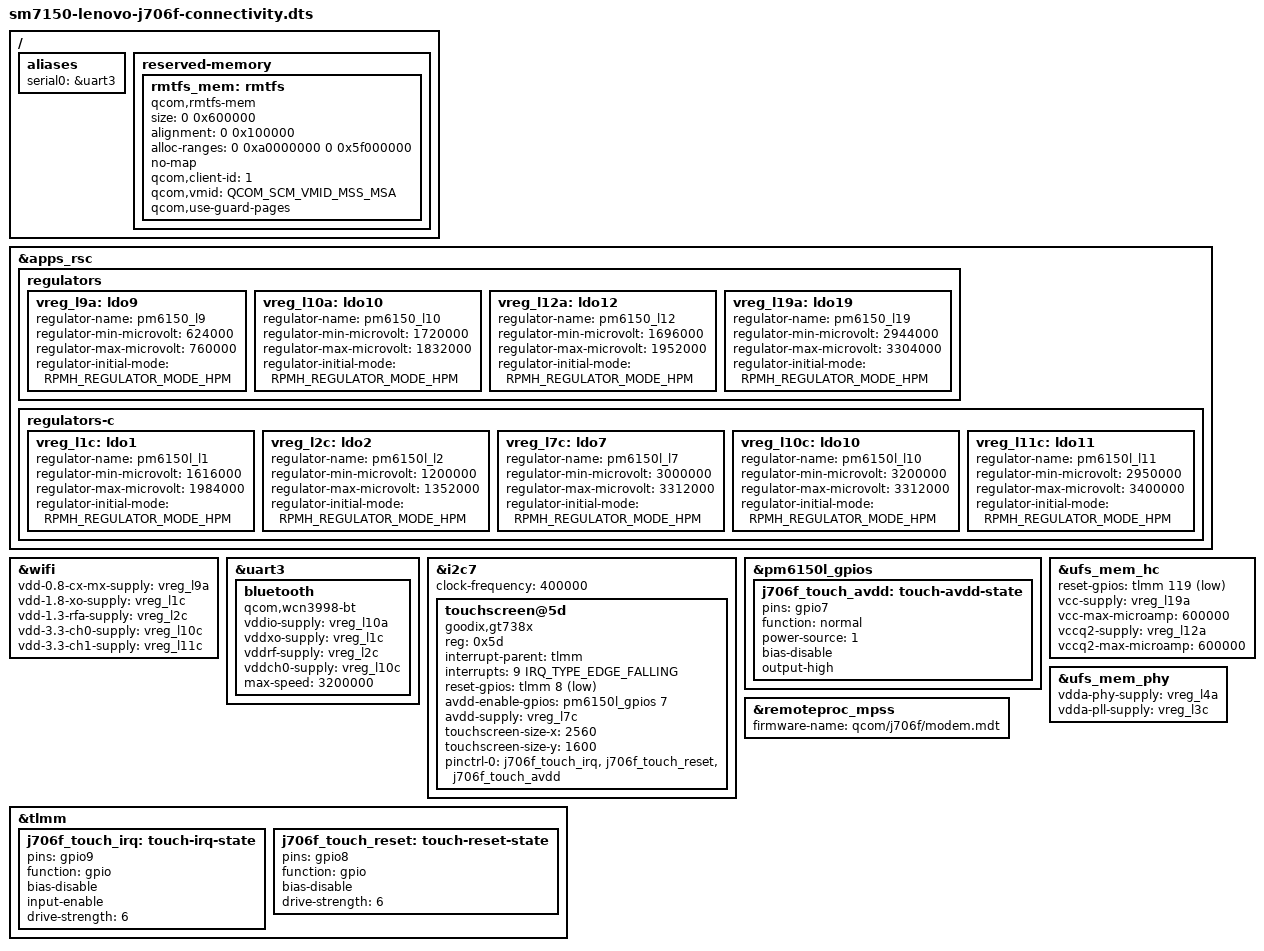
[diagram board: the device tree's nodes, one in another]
// SPDX-License-Identifier: BSD-3-Clause
#include "sm7150-lenovo-j706f-hall-power.dts"

&apps_rsc {
 regulators {
  vreg_l9a: ldo9 { regulator-name = "pm6150_l9"; regulator-min-microvolt = <624000>; regulator-max-microvolt = <760000>; regulator-initial-mode = <RPMH_REGULATOR_MODE_HPM>; };
  vreg_l10a: ldo10 { regulator-name = "pm6150_l10"; regulator-min-microvolt = <1720000>; regulator-max-microvolt = <1832000>; regulator-initial-mode = <RPMH_REGULATOR_MODE_HPM>; };
 };
 regulators-c {
  vreg_l1c: ldo1 { regulator-name = "pm6150l_l1"; regulator-min-microvolt = <1616000>; regulator-max-microvolt = <1984000>; regulator-initial-mode = <RPMH_REGULATOR_MODE_HPM>; };
  vreg_l2c: ldo2 { regulator-name = "pm6150l_l2"; regulator-min-microvolt = <1200000>; regulator-max-microvolt = <1352000>; regulator-initial-mode = <RPMH_REGULATOR_MODE_HPM>; };
  vreg_l7c: ldo7 { regulator-name = "pm6150l_l7"; regulator-min-microvolt = <3000000>; regulator-max-microvolt = <3312000>; regulator-initial-mode = <RPMH_REGULATOR_MODE_HPM>; };
  vreg_l10c: ldo10 { regulator-name = "pm6150l_l10"; regulator-min-microvolt = <3200000>; regulator-max-microvolt = <3312000>; regulator-initial-mode = <RPMH_REGULATOR_MODE_HPM>; };
  vreg_l11c: ldo11 { regulator-name = "pm6150l_l11"; regulator-min-microvolt = <2950000>; regulator-max-microvolt = <3400000>; regulator-initial-mode = <RPMH_REGULATOR_MODE_HPM>; };
 };
};
&wifi {
 vdd-0.8-cx-mx-supply = <&vreg_l9a>;
 vdd-1.8-xo-supply = <&vreg_l1c>;
 vdd-1.3-rfa-supply = <&vreg_l2c>;
 vdd-3.3-ch0-supply = <&vreg_l10c>;
 vdd-3.3-ch1-supply = <&vreg_l11c>;
 status = "okay";
};
&uart3 {
 status = "okay";
 bluetooth {
  compatible = "qcom,wcn3998-bt";
  vddio-supply = <&vreg_l10a>;
  vddxo-supply = <&vreg_l1c>;
  vddrf-supply = <&vreg_l2c>;
  vddch0-supply = <&vreg_l10c>;
  max-speed = <3200000>;
 };
};
&i2c7 {
 status = "okay";
 clock-frequency = <400000>;
 touchscreen@5d {
  compatible = "goodix,gt738x";
  reg = <0x5d>;
  interrupt-parent = <&tlmm>;
  interrupts = <9 IRQ_TYPE_EDGE_FALLING>;
  reset-gpios = <&tlmm 8 GPIO_ACTIVE_LOW>;
  avdd-enable-gpios = <&pm6150l_gpios 7 GPIO_ACTIVE_HIGH>;
  avdd-supply = <&vreg_l7c>;
  touchscreen-size-x = <2560>;
  touchscreen-size-y = <1600>;
  pinctrl-names = "default";
  pinctrl-0 = <&j706f_touch_irq &j706f_touch_reset &j706f_touch_avdd>;
 };
};
&tlmm {
 j706f_touch_irq: touch-irq-state { pins = "gpio9"; function = "gpio"; bias-disable; input-enable; drive-strength = <6>; };
 j706f_touch_reset: touch-reset-state { pins = "gpio8"; function = "gpio"; bias-disable; drive-strength = <6>; };
};
&pm6150l_gpios {
 j706f_touch_avdd: touch-avdd-state { pins = "gpio7"; function = "normal"; power-source = <1>; bias-disable; output-high; };
};

&remoteproc_mpss { firmware-name = "qcom/j706f/modem.mdt"; status = "okay"; };

/ { aliases { serial0 = &uart3; }; };

#include <dt-bindings/firmware/qcom,scm.h>
/ {
 reserved-memory {
  rmtfs_mem: rmtfs {
   compatible = "qcom,rmtfs-mem";
   size = <0 0x600000>;
   alignment = <0 0x100000>;
   alloc-ranges = <0 0xa0000000 0 0x5f000000>;
   no-map;
   qcom,client-id = <1>;
   qcom,vmid = <QCOM_SCM_VMID_MSS_MSA>;
   qcom,use-guard-pages;
  };
 };
};

/* Stock L12a/L19a supplies, read-only calibration access for RMTFS. */
&apps_rsc {
 regulators {
  vreg_l12a: ldo12 { regulator-name = "pm6150_l12"; regulator-min-microvolt = <1696000>; regulator-max-microvolt = <1952000>; regulator-initial-mode = <RPMH_REGULATOR_MODE_HPM>; };
  vreg_l19a: ldo19 { regulator-name = "pm6150_l19"; regulator-min-microvolt = <2944000>; regulator-max-microvolt = <3304000>; regulator-initial-mode = <RPMH_REGULATOR_MODE_HPM>; };
 };
};
&ufs_mem_hc {
 reset-gpios = <&tlmm 119 GPIO_ACTIVE_LOW>;
 vcc-supply = <&vreg_l19a>;
 vcc-max-microamp = <600000>;
 vccq2-supply = <&vreg_l12a>;
 vccq2-max-microamp = <600000>;
 status = "okay";
};
&ufs_mem_phy {
 vdda-phy-supply = <&vreg_l4a>;
 vdda-pll-supply = <&vreg_l3c>;
 status = "okay";
};
